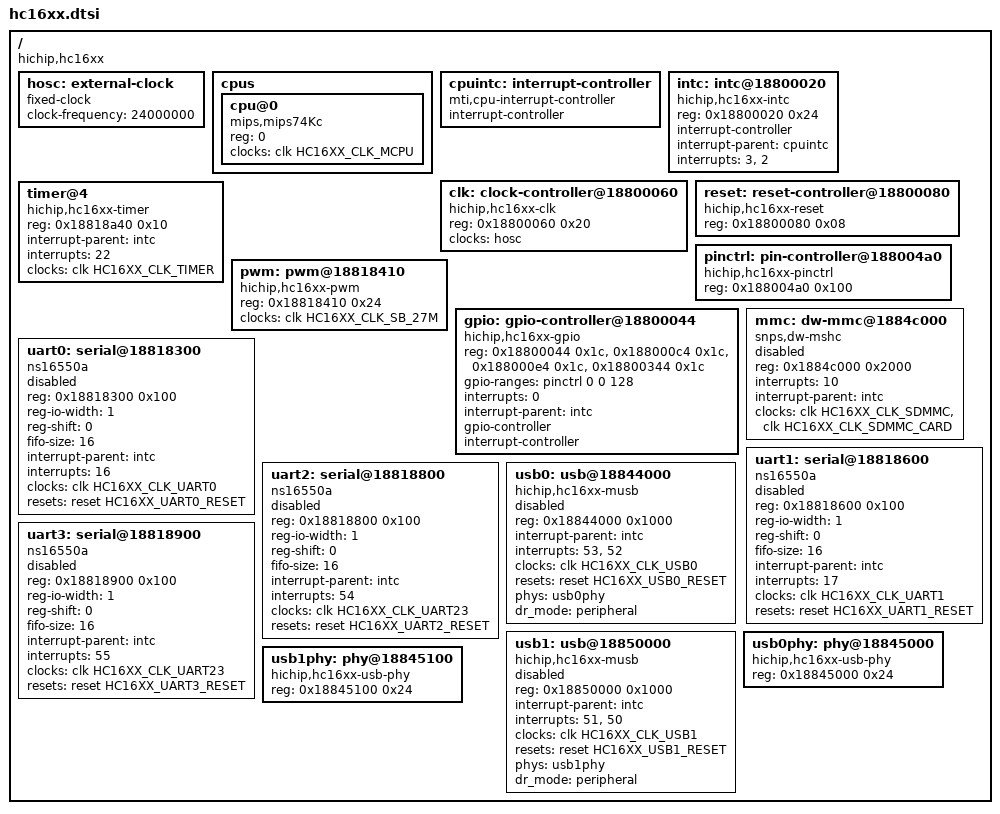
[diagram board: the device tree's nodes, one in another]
// SPDX-License-Identifier: (GPL-2.0-only OR BSD-2-Clause)
/dts-v1/;

#include <dt-bindings/clock/hichip,hc16xx-clock.h>
#include <dt-bindings/reset/hichip,hc16xx-reset.h>

/ {
	compatible = "hichip,hc16xx";
	#address-cells = <1>;
	#size-cells = <1>;

	hosc: external-clock {
		compatible = "fixed-clock";
		#clock-cells = <0>;
		clock-frequency = <24000000>;  /* 24 MHz, typical */
	};

	cpus: cpus {
		#address-cells = <1>;
		#size-cells = <0>;

		cpu@0 {
			device_type = "cpu";
			compatible = "mips,mips74Kc";
			reg = <0>;

			clocks = <&clk HC16XX_CLK_MCPU>;
			clock-names = "cpu";
		};
	};

	cpuintc: interrupt-controller {
		compatible = "mti,cpu-interrupt-controller";
		interrupt-controller;
		#address-cells = <0>;
		#interrupt-cells = <1>;
	};

	intc: intc@18800020 {
		compatible="hichip,hc16xx-intc";
		reg = <0x18800020 0x24>;

		interrupt-controller;
		#interrupt-cells = <1>;

		interrupt-parent = <&cpuintc>;
		interrupts = <3>, <2>;
	};

	clk: clock-controller@18800060 {
		compatible = "hichip,hc16xx-clk";
		reg = <0x18800060 0x20>;

		clocks = <&hosc>;
		clock-names = "hosc";

		#clock-cells = <1>;
	};

	reset: reset-controller@18800080 {
		compatible = "hichip,hc16xx-reset";
		reg = <0x18800080 0x08>;

		#reset-cells = <1>;
	};

	timer@4 {
		compatible = "hichip,hc16xx-timer";
		reg = <0x18818a40 0x10>;

		interrupt-parent = <&intc>;
		interrupts = <22>;

		clocks = <&clk HC16XX_CLK_TIMER>;
		clock-names = "counting";
	};

	pinctrl: pin-controller@188004a0 {
		compatible = "hichip,hc16xx-pinctrl";
		reg = <0x188004a0 0x100>;
	};

	pwm: pwm@18818410 {
		compatible = "hichip,hc16xx-pwm";

		reg = <0x18818410 0x24>;
		clocks = <&clk HC16XX_CLK_SB_27M>;

		#pwm-cells = <3>;
	};

	gpio: gpio-controller@18800044 {
		compatible = "hichip,hc16xx-gpio";
		reg =   <0x18800044 0x1c>, <0x188000c4 0x1c>,
                        <0x188000e4 0x1c>, <0x18800344 0x1c>;
                reg-names = "left", "bottom", "right", "top";
		gpio-ranges = <&pinctrl 0 0 128>;

		interrupts = <0>;
		interrupt-parent=<&intc>;

		gpio-controller;
		#gpio-cells = <2>;

		interrupt-controller;
		#interrupt-cells = <2>;
	};

	mmc: dw-mmc@1884c000 {
		compatible = "snps,dw-mshc";
		reg = <0x1884c000 0x2000>;
		#address-cells = <1>;
		#size-cells = <0>;

		interrupts = <10>;
		interrupt-parent=<&intc>;

		clocks = <&clk HC16XX_CLK_SDMMC>, <&clk HC16XX_CLK_SDMMC_CARD>;
		clock-names = "biu", "ciu";

		status = "disabled";
	};

	uart0: serial@18818300 {
		compatible = "ns16550a";
		reg = <0x18818300 0x100>;
		reg-io-width = <1>;
		reg-shift = <0>;
		fifo-size = <16>;

		interrupt-parent = <&intc>;
		interrupts = <16>;

		clocks = <&clk HC16XX_CLK_UART0>;
		clock-names = "baud";

		resets = <&reset HC16XX_UART0_RESET>;

		status = "disabled";
	};

	uart1: serial@18818600 {
		compatible = "ns16550a";
		reg = <0x18818600 0x100>;
		reg-io-width = <1>;
		reg-shift = <0>;
		fifo-size = <16>;

		interrupt-parent = <&intc>;
		interrupts = <17>;

		clocks = <&clk HC16XX_CLK_UART1>;
		clock-names = "baud";

		resets = <&reset HC16XX_UART1_RESET>;

		status = "disabled";
	};

	uart2: serial@18818800 {
		compatible = "ns16550a";
		reg = <0x18818800 0x100>;
		reg-io-width = <1>;
		reg-shift = <0>;
		fifo-size = <16>;

		interrupt-parent = <&intc>;
		interrupts = <54>;

		clocks = <&clk HC16XX_CLK_UART23>;
		clock-names = "baud";

		resets = <&reset HC16XX_UART2_RESET>;

		status = "disabled";
	};

	uart3: serial@18818900 {
		compatible = "ns16550a";
		reg = <0x18818900 0x100>;
		reg-io-width = <1>;
		reg-shift = <0>;
		fifo-size = <16>;

		interrupt-parent = <&intc>;
		interrupts = <55>;

		clocks = <&clk HC16XX_CLK_UART23>;
		clock-names = "baud";

		resets = <&reset HC16XX_UART3_RESET>;

		status = "disabled";
	};

	usb0: usb@18844000 {
		compatible = "hichip,hc16xx-musb";
		reg = <0x18844000 0x1000>;

		interrupt-parent = <&intc>;
		interrupts = <53>, <52>;
		interrupt-names = "mc", "dma";

		clocks = <&clk HC16XX_CLK_USB0>;
		resets = <&reset HC16XX_USB0_RESET>;
		phys   = <&usb0phy>;

		dr_mode = "peripheral";
		status = "disabled";
	};

	usb1: usb@18850000 {
		compatible = "hichip,hc16xx-musb";
		reg = <0x18850000 0x1000>;

		interrupt-parent = <&intc>;
		interrupts = <51>, <50>;
		interrupt-names = "mc", "dma";

		clocks = <&clk HC16XX_CLK_USB1>;
		resets = <&reset HC16XX_USB1_RESET>;
		phys   = <&usb1phy>;

		dr_mode = "peripheral";
		status = "disabled";
	};

	usb0phy: phy@18845000 {
		compatible = "hichip,hc16xx-usb-phy";
		reg = <0x18845000 0x24>;
		#phy-cells = <0>;
	};

	usb1phy: phy@18845100 {
		compatible = "hichip,hc16xx-usb-phy";
		reg = <0x18845100 0x24>;
		#phy-cells = <0>;
	};
};
